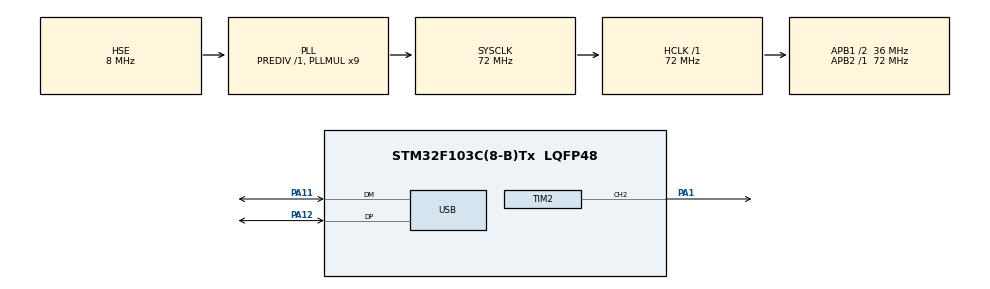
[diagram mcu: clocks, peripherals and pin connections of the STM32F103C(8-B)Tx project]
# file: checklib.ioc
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Dma.Request0=TIM2_CH2/CH4
Dma.TIM2_CH2/CH4.0.Direction=DMA_MEMORY_TO_PERIPH
Dma.TIM2_CH2/CH4.0.Instance=DMA1_Channel7
Dma.TIM2_CH2/CH4.0.MemDataAlignment=DMA_MDATAALIGN_WORD
Dma.TIM2_CH2/CH4.0.MemInc=DMA_MINC_ENABLE
Dma.TIM2_CH2/CH4.0.Mode=DMA_CIRCULAR
Dma.TIM2_CH2/CH4.0.PeriphDataAlignment=DMA_PDATAALIGN_WORD
Dma.TIM2_CH2/CH4.0.PeriphInc=DMA_PINC_DISABLE
Dma.TIM2_CH2/CH4.0.Priority=DMA_PRIORITY_HIGH
Mcu.Family=STM32F1
Mcu.Name=STM32F103C(8-B)Tx
Mcu.Package=LQFP48
NVIC.DMA1_Channel7_IRQn=true\:0\:0\:false\:false\:true\:false\:true\:true
NVIC.PriorityGroup=NVIC_PRIORITYGROUP_4
NVIC.USB_LP_CAN1_RX0_IRQn=true\:0\:0\:false\:false\:true\:false\:true\:true
PA1.GPIO_Speed=GPIO_SPEED_FREQ_HIGH
PA1.Signal=S_TIM2_CH2
PA11.Mode=Device
PA11.Signal=USB_DM
PA12.Mode=Device
PA12.Signal=USB_DP
PA13.Mode=Serial_Wire
PA13.Signal=SYS_JTMS-SWDIO
PA14.Mode=Serial_Wire
PA14.Signal=SYS_JTCK-SWCLK
PC14-OSC32_IN.Mode=LSE-External-Oscillator
PC14-OSC32_IN.Signal=RCC_OSC32_IN
PC15-OSC32_OUT.Mode=LSE-External-Oscillator
PC15-OSC32_OUT.Signal=RCC_OSC32_OUT
PD0-OSC_IN.Mode=HSE-External-Oscillator
PD0-OSC_IN.Signal=RCC_OSC_IN
PD1-OSC_OUT.Mode=HSE-External-Oscillator
PD1-OSC_OUT.Signal=RCC_OSC_OUT
ProjectManager.HeapSize=0x200
ProjectManager.StackSize=0x400
ProjectManager.TargetToolchain=CMake
RCC.AHBFreq_Value=72000000
RCC.APB1CLKDivider=RCC_HCLK_DIV2
RCC.APB1Freq_Value=36000000
RCC.APB1TimFreq_Value=72000000
RCC.APB2Freq_Value=72000000
RCC.APB2TimFreq_Value=72000000
RCC.HCLKFreq_Value=72000000
RCC.PLLMUL=RCC_PLL_MUL9
RCC.PLLSourceVirtual=RCC_PLLSOURCE_HSE
RCC.SYSCLKFreq_VALUE=72000000
RCC.SYSCLKSource=RCC_SYSCLKSOURCE_PLLCLK
RCC.USBFreq_Value=48000000
RCC.USBPrescaler=RCC_USBCLKSOURCE_PLL_DIV1_5
SH.S_TIM2_CH2.0=TIM2_CH2,PWM Generation2 CH2
TIM2.Channel-PWM\ Generation2\ CH2=TIM_CHANNEL_2
USB_DEVICE.CLASS_NAME_FS=CDC
USB_DEVICE.VirtualMode=Cdc
USB_DEVICE.VirtualModeFS=Cdc_FS
VP_TIM2_VS_ClockSourceINT.Mode=Internal
VP_USB_DEVICE_VS_USB_DEVICE_CDC_FS.Mode=CDC_FS
board=custom

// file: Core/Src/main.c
/* USER CODE BEGIN Header */
/**
  ******************************************************************************
  * @file           : main.c
  * @brief          : Main program body
  ******************************************************************************
  * @attention
  *
  * Copyright (c) 2025 STMicroelectronics.
  * All rights reserved.
  *
  * This software is licensed under terms that can be found in the LICENSE file
  * in the root directory of this software component.
  * If no LICENSE file comes with this software, it is provided AS-IS.
  *
  ******************************************************************************
  */
/* USER CODE END Header */
#include "main.h"
#include "dma.h"
#include "tim.h"
#include "usb_device.h"
#include "gpio.h"

/* USER CODE BEGIN Includes */
#include "ARGB.h"
/* USER CODE END Includes */

void SystemClock_Config(void);

/* USER CODE BEGIN 0 */
#include "globals.h"
/* USER CODE END 0 */

int main(void)
{

  /* MCU Configuration--------------------------------------------------------*/

  /* Reset of all peripherals, Initializes the Flash interface and the Systick. */
  HAL_Init();

  /* Configure the system clock */
  SystemClock_Config();

  /* Initialize all configured peripherals */
  MX_GPIO_Init();
  MX_DMA_Init();
  MX_TIM2_Init();
  MX_USB_DEVICE_Init();
  /* USER CODE BEGIN 2 */
  ARGB_Init();
  ARGB_SetBrightness(255);
  ARGB_Clear();
  /* USER CODE END 2 */

  /* Infinite loop */
  /* USER CODE BEGIN WHILE */
  while (1)
  {
    for(int32_t i = 0; i < NUM_PIXELS - 2; i++) {
      ARGB_SetRGB(i, leds_for_processing[(i*3)], leds_for_processing[(i*3) + 1], leds_for_processing[(i*3) + 2]);
    }

    while (ARGB_Ready() == ARGB_BUSY);
    if(data_ready) {
      ARGB_Show();
      data_ready = 0;
      temp_led_ptr = leds_for_processing;
      leds_for_processing = leds_for_writing;
      leds_for_writing = temp_led_ptr;
    }

    /* USER CODE END WHILE */

  }
}

void SystemClock_Config(void)
{
  RCC_OscInitTypeDef RCC_OscInitStruct = {0};
  RCC_ClkInitTypeDef RCC_ClkInitStruct = {0};
  RCC_PeriphCLKInitTypeDef PeriphClkInit = {0};

  /** Initializes the RCC Oscillators according to the specified parameters
  * in the RCC_OscInitTypeDef structure.
  */
  RCC_OscInitStruct.OscillatorType = RCC_OSCILLATORTYPE_HSE;
  RCC_OscInitStruct.HSEState = RCC_HSE_ON;
  RCC_OscInitStruct.HSEPredivValue = RCC_HSE_PREDIV_DIV1;
  RCC_OscInitStruct.HSIState = RCC_HSI_ON;
  RCC_OscInitStruct.PLL.PLLState = RCC_PLL_ON;
  RCC_OscInitStruct.PLL.PLLSource = RCC_PLLSOURCE_HSE;
  RCC_OscInitStruct.PLL.PLLMUL = RCC_PLL_MUL9;
  if (HAL_RCC_OscConfig(&RCC_OscInitStruct) != HAL_OK)
  {
    Error_Handler();
  }

  /** Initializes the CPU, AHB and APB buses clocks
  */
  RCC_ClkInitStruct.ClockType = RCC_CLOCKTYPE_HCLK|RCC_CLOCKTYPE_SYSCLK
                              |RCC_CLOCKTYPE_PCLK1|RCC_CLOCKTYPE_PCLK2;
  RCC_ClkInitStruct.SYSCLKSource = RCC_SYSCLKSOURCE_PLLCLK;
  RCC_ClkInitStruct.AHBCLKDivider = RCC_SYSCLK_DIV1;
  RCC_ClkInitStruct.APB1CLKDivider = RCC_HCLK_DIV2;
  RCC_ClkInitStruct.APB2CLKDivider = RCC_HCLK_DIV1;

  if (HAL_RCC_ClockConfig(&RCC_ClkInitStruct, FLASH_LATENCY_2) != HAL_OK)
  {
    Error_Handler();
  }
  PeriphClkInit.PeriphClockSelection = RCC_PERIPHCLK_USB;
  PeriphClkInit.UsbClockSelection = RCC_USBCLKSOURCE_PLL_DIV1_5;
  if (HAL_RCCEx_PeriphCLKConfig(&PeriphClkInit) != HAL_OK)
  {
    Error_Handler();
  }
}

void Error_Handler(void)
{
  __disable_irq();
  while (1)
  {
  }
}
